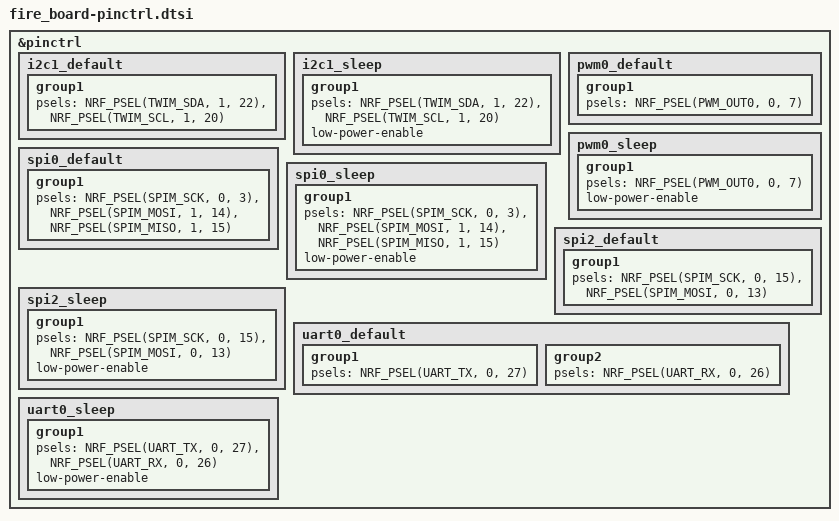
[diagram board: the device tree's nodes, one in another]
/*
 * Copyright (c) 2022 Nordic Semiconductor
 * SPDX-License-Identifier: Apache-2.0
 */

&pinctrl {

	i2c1_default: i2c1_default {
		group1 {
			psels = <NRF_PSEL(TWIM_SDA, 1, 22)>,
				    <NRF_PSEL(TWIM_SCL, 1, 20)>;
		};
	};

	i2c1_sleep: i2c1_sleep {
		group1 {
			psels = <NRF_PSEL(TWIM_SDA, 1, 22)>,
				    <NRF_PSEL(TWIM_SCL, 1, 20)>;
			low-power-enable;
		};
	};

    pwm0_default: pwm0_default {
        group1 {
            psels = <NRF_PSEL(PWM_OUT0, 0, 7)>;
        };
    };

    pwm0_sleep: pwm0_sleep {
        group1 {
            psels = <NRF_PSEL(PWM_OUT0, 0, 7)>;
            low-power-enable;
        };
    };
	
	spi0_default: spi0_default {
		group1 {
			psels = <NRF_PSEL(SPIM_SCK, 0, 3)>,
					<NRF_PSEL(SPIM_MOSI, 1, 14)>,
					<NRF_PSEL(SPIM_MISO, 1, 15)>;
		};
	};

	spi0_sleep: spi0_sleep {
		group1 {
			psels = <NRF_PSEL(SPIM_SCK, 0, 3)>,
					<NRF_PSEL(SPIM_MOSI, 1, 14)>,
					<NRF_PSEL(SPIM_MISO, 1, 15)>;
			low-power-enable;
		};
	};
	
	spi2_default: spi2_default {
		group1 {
			psels = <NRF_PSEL(SPIM_SCK, 0, 15)>,
					<NRF_PSEL(SPIM_MOSI, 0, 13)>;
		};
	};

	spi2_sleep: spi2_sleep {
		group1 {
			psels = <NRF_PSEL(SPIM_SCK, 0, 15)>,
					<NRF_PSEL(SPIM_MOSI, 0, 13)>;
			low-power-enable;
		};
	};
	
	uart0_default: uart0_default {
		group1 {
			psels = <NRF_PSEL(UART_TX, 0, 27)>;
		};
		group2 {
			psels = <NRF_PSEL(UART_RX, 0, 26)>;
		};
	};

	uart0_sleep: uart0_sleep {
		group1 {
			psels = <NRF_PSEL(UART_TX, 0, 27)>,
					<NRF_PSEL(UART_RX, 0, 26)>;
			low-power-enable;
		};
	};
};
